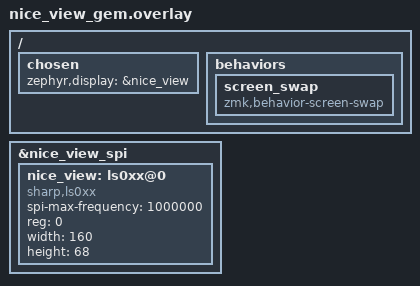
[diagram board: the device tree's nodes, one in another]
/*
 * Copyright (c) 2022 The ZMK Contributors
 *
 * SPDX-License-Identifier: MIT
 */

&nice_view_spi {
    status = "okay";
    nice_view: ls0xx@0 {
        compatible = "sharp,ls0xx";
        spi-max-frequency = <1000000>;
        reg = <0>;
        width = <160>;
        height = <68>;
    };
};

/ {
    chosen {
        zephyr,display = &nice_view;
    };

    behaviors {
        screen_swap: screen_swap {
            compatible = "zmk,behavior-screen-swap";
            #binding-cells = <0>;
        };
    };
};
